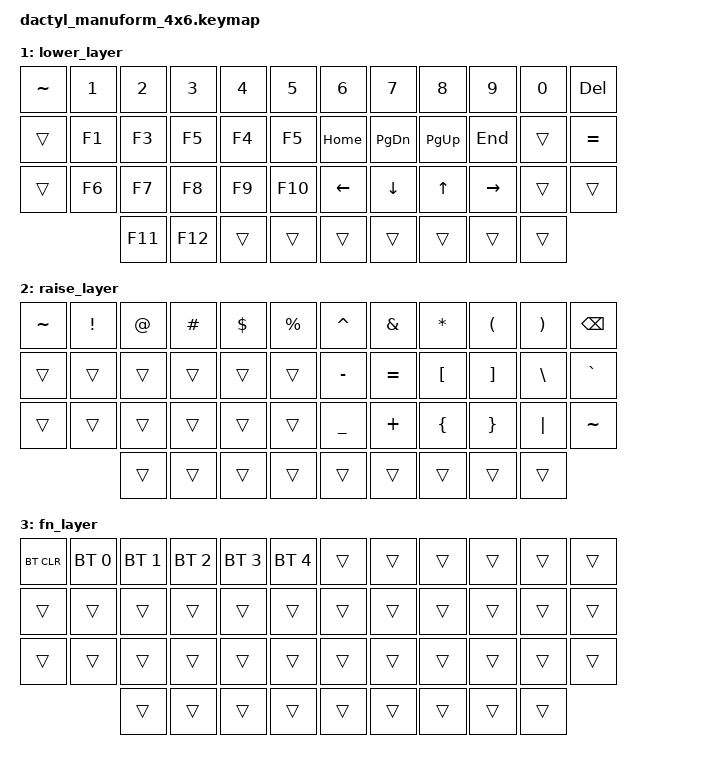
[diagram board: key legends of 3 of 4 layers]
/*
 * Copyright (c) 2020 The ZMK Contributors
 *
 * SPDX-License-Identifier: MIT
 *
 * Dactyl Manuform 4x6 + 5 thumb keys per side
 * Layout designed to stay close to conventional QWERTY
 *
 * 3 rows x 6 columns + 5 thumb keys = 46 keys total
 * Thumb keys use layer-tap: hold for layer, tap for key
 */

#include <behaviors.dtsi>
#include <dt-bindings/zmk/keys.h>
#include <dt-bindings/zmk/bt.h>

/ {
        behaviors {
                lt {
                        tapping-term-ms = <200>;
                };
        };

        keymap {
                compatible = "zmk,keymap";

                default_layer {
// -----------------------------------------------------------------------------------------
// | ESC  |  Q  |  W  |  E  |  R  |  T  |   |  Y  |  U  |  I  |  O  |  P  | BSPC |
// | TAB  |  A  |  S  |  D  |  F  |  G  |   |  H  |  J  |  K  |  L  |  ;  |  '   |
// | SHFT |  Z  |  X  |  C  |  V  |  B  |   |  N  |  M  |  ,  |  .  |  /  | SHFT |
//        | FN  | ALT | GUI |LWR/SPC|LCTL|   |RCTL |RSE/ENT| ALT|  [  |  ]  |
                        bindings = <
   &kp ESC   &kp Q  &kp W  &kp E  &kp R  &kp T    &kp Y  &kp U  &kp I     &kp O   &kp P    &kp BSPC
   &kp TAB   &kp A  &kp S  &kp D  &kp F  &kp G    &kp H  &kp J  &kp K     &kp L   &kp SEMI &kp SQT
   &kp LSHFT &kp Z  &kp X  &kp C  &kp V  &kp B    &kp N  &kp M  &kp COMMA &kp DOT &kp FSLH &kp RSHFT
             &mo 3  &kp LALT &kp LGUI &lt 1 SPACE &kp LCTRL   &kp RCTRL &lt 2 RET &kp RALT &kp LBKT &kp RBKT
                        >;
                };

                lower_layer {
// -----------------------------------------------------------------------------------------
// |  ~   |  1  |  2  |  3  |  4  |  5  |   |  6  |  7  |  8  |  9  |  10 | DEL  |
// |      |  F1 | F3  | F5  |  F4 |  F5 |   | HOME| PGDN| PGUP| END |     |  =   |
// |      |  F6 | F7  | F8  |  F9 |  F10|   | LFT | DWN |  UP | RGT |     |      |
//        |  F11| F12 |     |     |     |   |     |     |     |     |     |
                        bindings = <
   &kp TILDE &kp N1  &kp N2  &kp N3 &kp N4 &kp N5    &kp N6   &kp N7    &kp N8    &kp N9    &kp N0   &kp DEL
   &trans    &kp F1  &kp F3  &kp F5 &kp F4 &kp F5    &kp HOME &kp PG_DN &kp PG_UP &kp END   &trans   &kp EQUAL
   &trans    &kp F6  &kp F7  &kp F8 &kp F9 &kp F10   &kp LEFT &kp DOWN  &kp UP    &kp RIGHT &trans   &trans
                     &kp F11 &kp F12 &trans &trans    &trans   &trans    &trans    &trans    &trans
                        >;
                };

                raise_layer {
// -----------------------------------------------------------------------------------------
// |  ~   |  !  |  @  |  #  |  $  |  %  |   |  ^  |  &  |  *  |  (  |  )  | BSPC |
// |      |     |     |     |     |     |   |  -  |  =  |  [  |  ]  |  \  |  `   |
// |      |     |     |     |     |     |   |  _  |  +  |  {  |  }  | "|" |  ~   |
//        |     |     |     |     |     |   |     |     |     |     |     |
                        bindings = <
   &kp TILDE &kp EXCL &kp AT &kp HASH &kp DLLR &kp PRCNT   &kp CARET &kp AMPS  &kp ASTRK &kp LPAR &kp RPAR &kp BSPC
   &trans    &trans   &trans &trans   &trans   &trans      &kp MINUS &kp EQUAL &kp LBKT  &kp RBKT &kp BSLH &kp GRAVE
   &trans    &trans   &trans &trans   &trans   &trans      &kp UNDER &kp PLUS  &kp LBRC  &kp RBRC &kp PIPE &kp TILDE
                      &trans &trans   &trans   &trans      &trans    &trans    &trans    &trans   &trans
                        >;
                };

                fn_layer {
// -----------------------------------------------------------------------------------------
// | BTCLR| BT1 | BT2 | BT3 | BT4 | BT5 |   |     |     |     |     |     |      |
// |      |     |     |     |     |     |   |     |     |     |     |     |      |
// |      |     |     |     |     |     |   |     |     |     |     |     |      |
//        |     |     |     |     |     |   |     |     |     |     |     |
                        bindings = <
   &bt BT_CLR &bt BT_SEL 0 &bt BT_SEL 1 &bt BT_SEL 2 &bt BT_SEL 3 &bt BT_SEL 4   &trans &trans &trans &trans &trans &trans
   &trans     &trans       &trans       &trans       &trans       &trans           &trans &trans &trans &trans &trans &trans
   &trans     &trans       &trans       &trans       &trans       &trans           &trans &trans &trans &trans &trans &trans
                           &trans       &trans       &trans       &trans           &trans &trans &trans &trans &trans
                        >;
                };
        };
};
